# ESP32-C6 register map
Vendor: ESPRESSIF SYSTEMS (SHANGHAI) CO., LTD.; Series: ESP32 C-Series; File version: 12
CPU: RV32IMAC r0p0, little endian, no MPU, no FPU, 0 interrupt priority bits
Address unit: 32 bits
Registers are 32-bit, read-write, reset 0x0 unless marked. A register's access mark holds for its fields unless they carry their own. Offsets are from the block's base; [hi:lo] are bit positions; lines under a group give offsets from that group; {n}, {i} and the like mark numbered series.

## RSA — RSA (Rivest Shamir Adleman) Accelerator
Base 0x6008A000
{0x0+4i} M_MEM[{i}] (i=0..95) — The memory that stores M
{0x200+4i} Z_MEM[{i}] (i=0..95) — The memory that stores Z
{0x400+4i} Y_MEM[{i}] (i=0..95) — The memory that stores Y
{0x600+4i} X_MEM[{i}] (i=0..95) — The memory that stores X
0x800 M_PRIME — RSA M_prime register
  [31:0] M_PRIME — Those bits stores m'
0x804 MODE — RSA mode register
  [6:0] MODE — rsa mode (rsa length).
0x808 QUERY_CLEAN ro — RSA query clean register
  [0] QUERY_CLEAN
0x80C SET_START_MODEXP wo — RSA modular exponentiation trigger register.
  [0] SET_START_MODEXP — start modular exponentiation
0x810 SET_START_MODMULT wo — RSA modular multiplication trigger register.
  [0] SET_START_MODMULT — start modular multiplication
0x814 SET_START_MULT wo — RSA normal multiplication trigger register.
  [0] SET_START_MULT — start multiplicaiton
0x818 QUERY_IDLE ro — RSA query idle register
  [0] QUERY_IDLE — query rsa idle. 1'b0: busy, 1'b1: idle
0x81C INT_CLR — RSA interrupt clear register
  [0] INT_CLR — set this bit to clear RSA interrupt.
0x820 CONSTANT_TIME reset 0x1 — RSA constant time option register
  [0] CONSTANT_TIME — Configure this bit to 0 for acceleration. 0: with acceleration, 1: without acceleration(defalut).
0x824 SEARCH_ENABLE — RSA search option
  [0] SEARCH_ENABLE — Configure this bit to 1 for acceleration. 1: with acceleration, 0: without acceleration(default). This option should be used together with RSA_SEARCH_POS.
0x828 SEARCH_POS — RSA search position configure register
  [11:0] SEARCH_POS — Configure this field to set search position. This field should be used together with RSA_SEARCH_ENABLE. The field is only meaningful when RSA_SEARCH_ENABLE is high.
0x82C INT_ENA — RSA interrupt enable register
  [0] INT_ENA — Set this bit to enable interrupt that occurs when rsa calculation is done. 1'b0: disable, 1'b1: enable(default).
0x830 DATE — RSA version control register

## SHA — SHA (Secure Hash Algorithm) Accelerator
Base 0x60089000
0x00 MODE — Initial configuration register.
  [2:0] MODE — Sha mode.
0x04 T_STRING — SHA 512/t configuration register 0.
  [31:0] T_STRING — Sha t_string (used if and only if mode == SHA_512/t).
0x08 T_LENGTH — SHA 512/t configuration register 1.
  [5:0] T_LENGTH — Sha t_length (used if and only if mode == SHA_512/t).
0x0C DMA_BLOCK_NUM — DMA configuration register 0.
  [5:0] DMA_BLOCK_NUM — Dma-sha block number.
0x10 START wo — Typical SHA configuration register 0.
  [0] START — Write 1 to start Typical SHA calculation.
0x14 CONTINUE wo — Typical SHA configuration register 1.
  [0] CONTINUE — Write 1 to continue Typical SHA calculation.
0x18 BUSY ro
  [0] STATE — Sha busy state. 1'b0: idle. 1'b1: busy.
0x1C DMA_START wo — DMA configuration register 1.
  [0] DMA_START — Start dma-sha.
0x20 DMA_CONTINUE wo — DMA configuration register 2.
  [0] DMA_CONTINUE — Continue dma-sha.
0x24 CLEAR_IRQ wo — Interrupt clear register.
  [0] CLEAR_INTERRUPT — Clear sha interrupt.
0x28 IRQ_ENA — Interrupt enable register.
  [0] INTERRUPT_ENA — Sha interrupt enable register. 1'b0: disable(default). 1'b1: enable.
0x2C DATE
{0x40+4i} H_MEM[{i}] (i=0..7) access not given — Sha H memory which contains intermediate hash or finial hash.
{0x80+4i} M_MEM[{i}] (i=0..15) access not given — Sha M memory which contains message.

## SOC_ETM — Event Task Matrix
Base 0x60013000
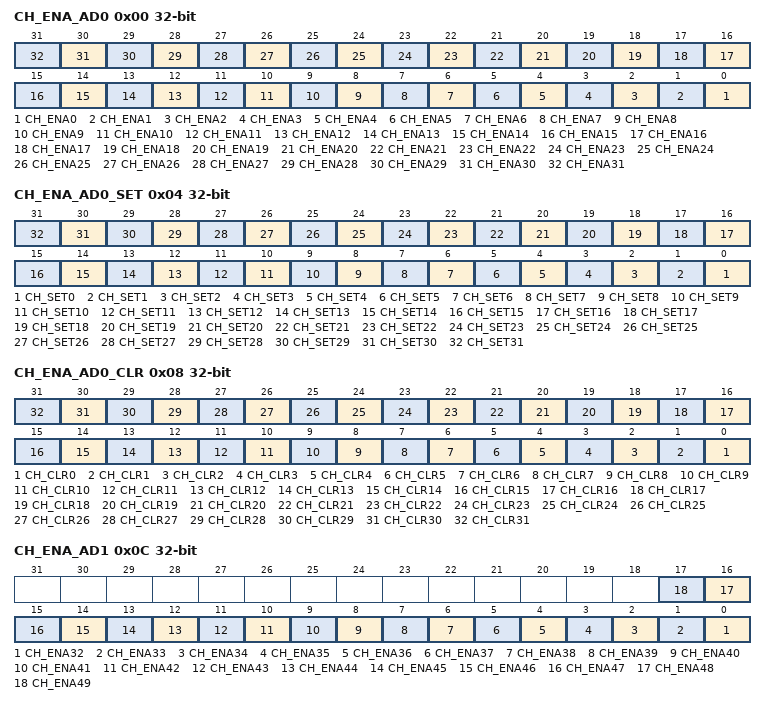
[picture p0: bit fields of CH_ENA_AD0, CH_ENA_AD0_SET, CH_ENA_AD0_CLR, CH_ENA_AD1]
0x00 CH_ENA_AD0 — channel enable register
  [n] CH_ENA{n} (n=0..31) — ch{n} enable
0x04 CH_ENA_AD0_SET wo — channel enable set register
  [n] CH_SET{n} (n=0..31) — ch{n} set
0x08 CH_ENA_AD0_CLR wo — channel enable clear register
  [n] CH_CLR{n} (n=0..31) — ch{n} clear
0x0C CH_ENA_AD1 — channel enable register
  [n-32] CH_ENA{n} (n=32..49) — ch{n} enable
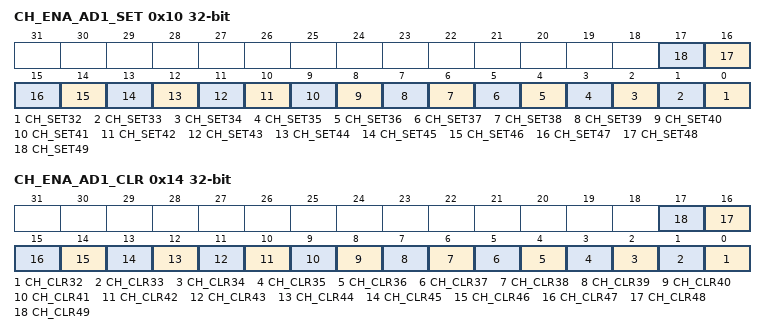
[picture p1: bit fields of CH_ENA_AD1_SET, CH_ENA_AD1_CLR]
0x10 CH_ENA_AD1_SET wo — channel enable set register
  [n-32] CH_SET{n} (n=32..49) — ch{n} set
0x14 CH_ENA_AD1_CLR wo — channel enable clear register
  [n-32] CH_CLR{n} (n=32..49) — ch{n} clear
{0x18+8i} CH{i} (i=0..49) group — Cluster CH{i}, containing CH*_EVT_ID, CH*_TASK_ID
  0x00 EVT_ID — channel0 event id register
    [7:0] EVT_ID — ch0_evt_id
  0x04 TASK_ID — channel0 task id register
    [7:0] TASK_ID — ch0_task_id
0x1A8 CLK_EN — etm clock enable register
  [0] CLK_EN — clock enable
0x1AC DATE — etm date register
